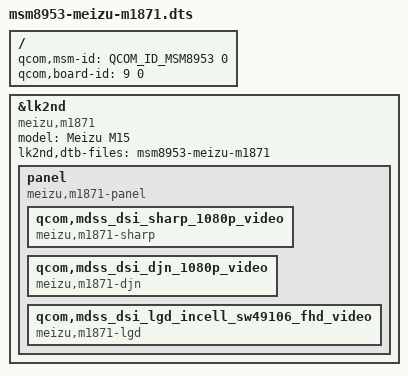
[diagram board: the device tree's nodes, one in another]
// SPDX-License-Identifier: BSD-3-Clause

/dts-v1/;

#include <skeleton64.dtsi>
#include <lk2nd.dtsi>

/ {
	qcom,msm-id = <QCOM_ID_MSM8953 0>;
	qcom,board-id = <9 0>;
};

&lk2nd {
	model = "Meizu M15";
	compatible = "meizu,m1871";

	lk2nd,dtb-files = "msm8953-meizu-m1871";

	panel {
		compatible = "meizu,m1871-panel", "lk2nd,panel";

		qcom,mdss_dsi_sharp_1080p_video {
			compatible = "meizu,m1871-sharp";
		};

		qcom,mdss_dsi_djn_1080p_video {
			compatible = "meizu,m1871-djn";
		};

		qcom,mdss_dsi_lgd_incell_sw49106_fhd_video {
			compatible = "meizu,m1871-lgd";
		};
	};
};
